# ARMSS_VIC_CFG register map
Vendor: Texas Instruments
Peripheral module from a debugger description file (folder J7VCL).
Registers are 32-bit, read-only, reset 0x0 unless marked. A register's access mark holds for its fields unless they carry their own. Offsets are as the file gives them; lines under a group give offsets from that group; [hi:lo] are bit positions; {n}, {i} and the like mark numbered series; 'fields as' and 'values as' point back to an identical list; <NAME> marks a mode.

## ARMSS_VIC_CFG
0x00 R5FSS_VIM_PID reset 0x60900001 — This register contains the major and minor revisions for the module.
  [31:0] REV — TI internal data. Identifies revision of peripheral.
0x04 R5FSS_VIM_INFO reset 0x200 — This contains information about the configuration of the R5FSS_VIM.
  [10:0] INTERRUPTS — Indicates the number of interrupts supported by the VIM.
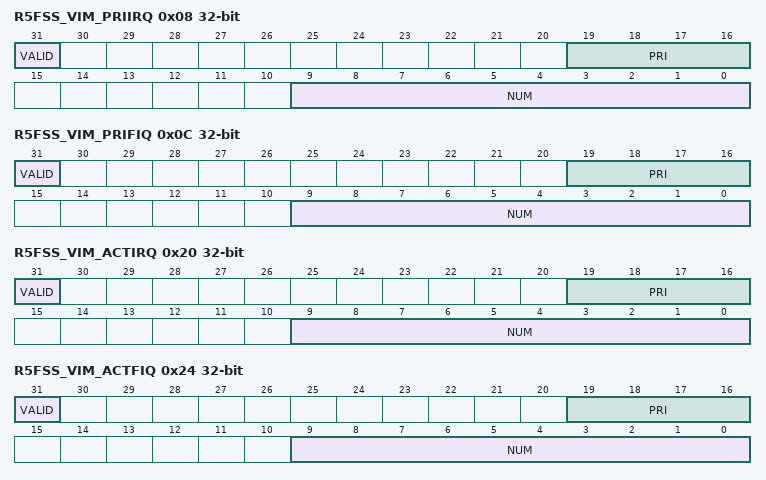
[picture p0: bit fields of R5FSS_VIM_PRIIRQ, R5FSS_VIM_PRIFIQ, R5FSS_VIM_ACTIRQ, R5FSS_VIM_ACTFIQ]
0x08 R5FSS_VIM_PRIIRQ — This register contains the number of the highest priority pending IRQ.
  [31] VALID — This field indicates if the NUM field of this register is valid.
  [19:16] PRI — This field indicates the priority of the pending IRQ interrupt.
  [9:0] NUM — This field indicates the interrupt number of the pending IRQ interrupt with the highest priority.
0x0C R5FSS_VIM_PRIFIQ — This register contains the number of the highest priority pending FIQ.
  [31] VALID — This field indicates if the NUM field of this register is valid.
  [19:16] PRI — This field indicates the priority of the pending FIQ interrupt.
  [9:0] NUM — This field indicates the interrupt number of the pending FIQ interrupt with the highest priority.
0x10 R5FSS_VIM_IRQGSTS — This register indicates which groups of interrupts have pending, unmasked IRQ interrupts.
  [31:0] STS — This field indicates that one or more interrupts in group M are mapped to IRQ, unmasked, and pending. Bit 0 corresponds to group 0, bit 1 corresponds to group 1, etc. The interrupts associated with each group are [(M*32)+31:M*32]
0x14 R5FSS_VIM_FIQGSTS — This register indicates which groups of interrupts have pending, unmasked FIQ interrupts.
  [31:0] STS — This field indicates that one or more interrupts in group M are mapped to FIQ, unmasked, and pending. Bit 0 corresponds to group 0, bit 1 corresponds to group 1, etc. The interrupts associated with each group are [(M*32)+31:M*32]
0x18 R5FSS_VIM_IRQVEC — This register contains the 32-bit interrupt vector address of the currently pending IRQ.
  [31:2] ADDR — This field contains the upper 30 bits of the 32-bit interrupt vector address (addresses must be 32-bit aligned) of the currently pending highest priority IRQ (as indicated by the
0x1C R5FSS_VIM_FIQVEC — This register contains the 32-bit interrupt vector address of the currently pending FIQ.
  [31:2] ADDR — This field contains the upper 30 bits of the 32-bit interrupt vector address (addresses must be 32-bit aligned) of the currently pending highest priority FIQ (as indicated by the
0x20 R5FSS_VIM_ACTIRQ — This register contains the number of the active IRQ.
  [31] VALID — This field indicates if the NUM field of this register is valid.
  [19:16] PRI — This field indicates the priority of the active IRQ interrupt.
  [9:0] NUM — This field indicates the interrupt number of the active IRQ interrupt.
0x24 R5FSS_VIM_ACTFIQ — This register contains the number of the active FIQ.
  [31] VALID — This field indicates if the NUM field of this register is valid.
  [19:16] PRI — This field indicates the priority of the active FIQ interrupt.
  [9:0] NUM — This field indicates the interrupt number of the active FIQ interrupt.
0x30 R5FSS_VIM_DEDVEC access per field — This register contains the 32-bit interrupt vector address to be used as a default in case of a DED error in any of the vectors.
  [31:2] ADDR rw — This field contains the upper 30 bits of the 32-bit interrupt vector address (the address must be 32-bit aligned) of an interrupt to be used if an uncorrectable double-bit error (DED) is detected in any of the interrupt vector addresses.
0x400 R5FSS_VIM_RAW_j access not given — This register indicates the raw status of the events in group M. Offset = 400h + (j * 20h); where j = 0h to Fh.
  [31:0] STS — This is the raw status of the events in group M. Each bit corresponds to event Q, where Q = M*32+bit (example: bit 0 is event M*32+0, bit 1 is M*32+1, etc). (access RW1S)
0x404 R5FSS_VIM_STS_j access not given — This register indicates the masked status of the events in group M. Offset = 404h + (j * 20h); where j = 0h to Fh.
  [31:0] MSK — This is the masked status of the events in group M. Each bit corresponds to event Q, where Q = M*32+bit (example: bit 0 is event M*32+0, bit 1 is M*32+1, etc). (access RW1C)
0x408 R5FSS_VIM_INTR_EN_SET_j access not given — This register is used to enable the mask for the events in group M. Offset = 408h + (j * 20h); where j = 0h to Fh.
  [31:0] MSK — This field is used to enable the mask of events in group M. Each bit corresponds to event Q, where Q = M*32+bit (example: bit 0 is event M*32+0, bit 1 is M*32+1, etc). (access RW1S)
0x40C R5FSS_VIM_INTR_EN_CLR_j access not given — This register is used to disable the mask for the events in group M. Offset = 40Ch + (j * 20h); where j = 0h to Fh.
  [31:0] MSK — This field is used to disable the mask of events in group M. Each bit corresponds to event Q, where Q = M*32+bit (example: bit 0 is event M*32+0, bit 1 is M*32+1, etc). (access RW1C)
0x410 R5FSS_VIM_IRQSTS_j access not given — This register indicates the masked status of the events in Group M that are also mapped as IRQs. Offset = 410h + (j * 20h); where j = 0h to Fh.
  [31:0] MSK — This is the masked status of the events in group M that are mapped to IRQ. Each bit corresponds to event Q, where Q = M*32+bit (example: bit 0 is event M*32+0, bit 1 is M*32+1, etc). (access RW1C)
0x414 R5FSS_VIM_FIQSTS_j access not given — This register indicates the masked status of the events in group M that are also mapped as FIQs. Offset = 414h + (j * 20h); where j = 0h to Fh.
  [31:0] MSK — This is the masked status of the events in group M that are mapped to FIQ. Each bit corresponds to event Q, where Q = M*32+bit (example: bit 0 is event M*32+0, bit 1 is M*32+1, etc). (access RW1C)
0x418 R5FSS_VIM_INTMAP_j rw — This register is used to map interrupts as IRQ or FIQ. Offset = 418h + (j * 20h); where j = 0h to Fh.
  [31:0] MSK — This field is used to indicate which interrupt the corresponding event influences (if enabled) for event group M. Each bit corresponds to event Q, where Q = M*32+bit (example: bit 0 is event M*32+0, bit 1 is M*32+1, etc).
0x41C R5FSS_VIM_INTTYPE_j rw — This register indicates whether an interrupt is a pulse or level source. Offset = 41Ch + (j * 20h); where j = 0h to Fh.
  [31:0] MSK — This field is used to indicate whether the source of an interrupt is a level (default) or a pulse for event group M. Each bit corresponds to event Q, where Q = M*32+bit (example: bit 0 is event M*32+0, bit 1 is M*32+1, etc).
0x1000 R5FSS_VIM_PRI_INT_j access per field reset 0xF — This register is used to set the priority of interrupt Q. Offset = 1000h + (j * 4h); where j = 0h to 1FFh.
  [3:0] VAL rw — This is the priority for interrupt Q. If two interrupts have the same priority, then whichever interrupt has the lower number Q wins arbitration.
0x2000 R5FSS_VIM_VEC_INT_j access per field — This register contains the vector address associated with interrupt Q. Offset = 2000h + (j * 4h); where j = 0h to 1FFh.
  [31:2] VAL rw — These are the upper 30 bits of the 32-bit vector address associated with interrupt Q. It is the address that will be reflected in the
